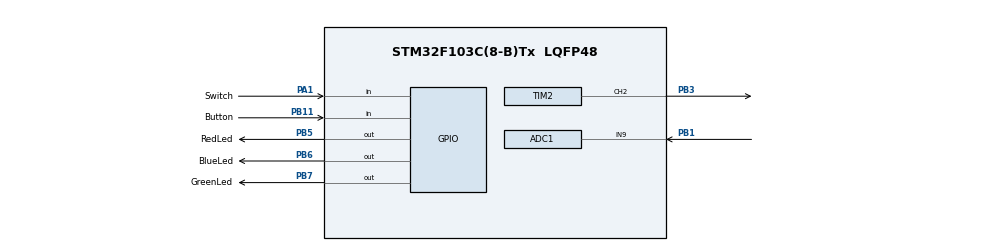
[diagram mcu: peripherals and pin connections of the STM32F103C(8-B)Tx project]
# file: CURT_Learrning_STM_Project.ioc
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Mcu.Family=STM32F1
RCC.PLLSourceVirtual=RCC_PLLSOURCE_HSE
ADC1.Rank-0\#ChannelRegularConversion=1
PD1-OSC_OUT.Mode=HSE-External-Oscillator
ADC1.ContinuousConvMode=ENABLE
PB11.GPIO_Label=Button
PB6.GPIO_Label=BlueLed
PD0-OSC_IN.Signal=RCC_OSC_IN
PB11.GPIO_PuPd=GPIO_PULLDOWN
TIM2.Channel-PWM\ Generation2\ CH2=TIM_CHANNEL_2
PB11.Signal=GPIO_Input
RCC.SYSCLKSource=RCC_SYSCLKSOURCE_HSE
ProjectManager.StackSize=0x400
PD1-OSC_OUT.Signal=RCC_OSC_OUT
PA13.Signal=SYS_JTMS-SWDIO
SH.S_TIM2_CH2.0=TIM2_CH2,PWM Generation2 CH2
ProjectManager.TargetToolchain=STM32CubeIDE
PB6.Signal=GPIO_Output
PB5.PinState=GPIO_PIN_RESET
RCC.USBFreq_Value=16000000
PA1.GPIO_PuPd=GPIO_PULLDOWN
PA1.Signal=GPIO_Input
PD0-OSC_IN.Mode=HSE-External-Oscillator
ADC1.Channel-0\#ChannelRegularConversion=ADC_CHANNEL_9
board=custom
RCC.APB2Freq_Value=8000000
VP_TIM2_VS_ClockSourceINT.Mode=Internal
PA14.Mode=Serial_Wire
PA1.GPIO_Label=Switch
PB7.Signal=GPIO_Output
TIM2.Period=624
PA13.Mode=Serial_Wire
Mcu.Name=STM32F103C(8-B)Tx
ADC1.SamplingTime-0\#ChannelRegularConversion=ADC_SAMPLETIME_1CYCLE_5
PB7.GPIO_Label=GreenLed
PB3.Signal=S_TIM2_CH2
Mcu.Package=LQFP48
PB5.Signal=GPIO_Output
TIM2.Prescaler=127
PB1.Signal=ADCx_IN9
ADC1.master=1
PB5.GPIO_PuPd=GPIO_PULLDOWN
PA14.Signal=SYS_JTCK-SWCLK
ProjectManager.HeapSize=0x200
SH.ADCx_IN9.0=ADC1_IN9,IN9
NVIC.PriorityGroup=NVIC_PRIORITYGROUP_4
ADC1.NbrOfConversionFlag=1
PB5.GPIO_Label=RedLed
RCC.APB1Freq_Value=8000000

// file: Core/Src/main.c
/* USER CODE BEGIN Header */
/**
  ******************************************************************************
  * @file           : main.c
  * @brief          : Main program body
  ******************************************************************************
  * @attention
  *
  * <h2><center>&copy; Copyright (c) 2024 STMicroelectronics.
  * All rights reserved.</center></h2>
  *
  * This software component is licensed by ST under BSD 3-Clause license,
  * the "License"; You may not use this file except in compliance with the
  * License. You may obtain a copy of the License at:
  *                        opensource.org/licenses/BSD-3-Clause
  *
  ******************************************************************************
  */
/* USER CODE END Header */
#include "main.h"

ADC_HandleTypeDef hadc1;

TIM_HandleTypeDef htim2;

void SystemClock_Config(void);
static void MX_GPIO_Init(void);
static void MX_ADC1_Init(void);
static void MX_TIM2_Init(void);

/* USER CODE BEGIN 0 */

uint32_t ADC_Value;

/* USER CODE END 0 */

int main(void)
{

  /* MCU Configuration--------------------------------------------------------*/

  /* Reset of all peripherals, Initializes the Flash interface and the Systick. */
  HAL_Init();

  /* Configure the system clock */
  SystemClock_Config();

  /* Initialize all configured peripherals */
  MX_GPIO_Init();
  MX_ADC1_Init();
  MX_TIM2_Init();
  /* USER CODE BEGIN 2 */

  HAL_TIM_PWM_Start(&htim2, TIM_CHANNEL_2);
  HAL_ADC_Start(&hadc1);
  /*SystemCoreClockUpdate();
  SysTick_Config(SystemCoreClock/100);
  SysTick -> CTRL = 0;
  SysTick -> VAL  = 0;
  SysTick -> CTRL = (SysTick_CTRL_CLKSOURCE_Msk | SysTick_CTRL_ENABLE_Msk | SysTick_CTRL_CLKSOURCE_Msk);*/

  /* USER CODE END 2 */

  /* Infinite loop */
  while (1)
  {

    /* USER CODE BEGIN 3 */

	  HAL_ADC_PollForConversion(&hadc1, 1000);
	  ADC_Value = HAL_ADC_GetValue(&hadc1);

	  if( HAL_GPIO_ReadPin(Switch_GPIO_Port, Switch_Pin) == 1)
	  {
		  __HAL_TIM_SET_COMPARE(&htim2, TIM_CHANNEL_2, ADC_Value);
		  //HAL_Delay(3);
	  }
	  else
	  {
		  __HAL_TIM_SET_COMPARE(&htim2, TIM_CHANNEL_2, 0);
	  }

	  if( HAL_GPIO_ReadPin(Button_GPIO_Port, Button_Pin) == 1)
	  {
	  	  HAL_GPIO_WritePin(RedLed_GPIO_Port, RedLed_Pin, 1);
	  	  //HAL_SYSTICK_Config(1000);

	  }

  }
  /* USER CODE END 3 */
}

void SysTick_Handler(void)
{
	if(HAL_GPIO_ReadPin(RedLed_GPIO_Port, RedLed_Pin) == 1)
	{
		HAL_IncTick();
	}

  if(uwTick >= 1000)
  {
	  HAL_GPIO_TogglePin(RedLed_GPIO_Port, RedLed_Pin);
	  uwTick = 0;
  }
  //HAL_GPIO_WritePin(RedLed_GPIO_Port, RedLed_Pin, GPIO_PIN_RESET);
}

void SystemClock_Config(void)
{
  RCC_OscInitTypeDef RCC_OscInitStruct = {0};
  RCC_ClkInitTypeDef RCC_ClkInitStruct = {0};
  RCC_PeriphCLKInitTypeDef PeriphClkInit = {0};

  /** Initializes the RCC Oscillators according to the specified parameters
  * in the RCC_OscInitTypeDef structure.
  */
  RCC_OscInitStruct.OscillatorType = RCC_OSCILLATORTYPE_HSE;
  RCC_OscInitStruct.HSEState = RCC_HSE_ON;
  RCC_OscInitStruct.PLL.PLLState = RCC_PLL_NONE;
  if (HAL_RCC_OscConfig(&RCC_OscInitStruct) != HAL_OK)
  {
    Error_Handler();
  }
  /** Initializes the CPU, AHB and APB buses clocks
  */
  RCC_ClkInitStruct.ClockType = RCC_CLOCKTYPE_HCLK|RCC_CLOCKTYPE_SYSCLK
                              |RCC_CLOCKTYPE_PCLK1|RCC_CLOCKTYPE_PCLK2;
  RCC_ClkInitStruct.SYSCLKSource = RCC_SYSCLKSOURCE_HSE;
  RCC_ClkInitStruct.AHBCLKDivider = RCC_SYSCLK_DIV1;
  RCC_ClkInitStruct.APB1CLKDivider = RCC_HCLK_DIV1;
  RCC_ClkInitStruct.APB2CLKDivider = RCC_HCLK_DIV1;

  if (HAL_RCC_ClockConfig(&RCC_ClkInitStruct, FLASH_LATENCY_0) != HAL_OK)
  {
    Error_Handler();
  }
  PeriphClkInit.PeriphClockSelection = RCC_PERIPHCLK_ADC;
  PeriphClkInit.AdcClockSelection = RCC_ADCPCLK2_DIV2;
  if (HAL_RCCEx_PeriphCLKConfig(&PeriphClkInit) != HAL_OK)
  {
    Error_Handler();
  }
}

static void MX_ADC1_Init(void)
{

  ADC_ChannelConfTypeDef sConfig = {0};

  /** Common config
  */
  hadc1.Instance = ADC1;
  hadc1.Init.ScanConvMode = ADC_SCAN_DISABLE;
  hadc1.Init.ContinuousConvMode = ENABLE;
  hadc1.Init.DiscontinuousConvMode = DISABLE;
  hadc1.Init.ExternalTrigConv = ADC_SOFTWARE_START;
  hadc1.Init.DataAlign = ADC_DATAALIGN_RIGHT;
  hadc1.Init.NbrOfConversion = 1;
  if (HAL_ADC_Init(&hadc1) != HAL_OK)
  {
    Error_Handler();
  }
  /** Configure Regular Channel
  */
  sConfig.Channel = ADC_CHANNEL_9;
  sConfig.Rank = ADC_REGULAR_RANK_1;
  sConfig.SamplingTime = ADC_SAMPLETIME_1CYCLE_5;
  if (HAL_ADC_ConfigChannel(&hadc1, &sConfig) != HAL_OK)
  {
    Error_Handler();
  }

}

static void MX_TIM2_Init(void)
{

  TIM_ClockConfigTypeDef sClockSourceConfig = {0};
  TIM_MasterConfigTypeDef sMasterConfig = {0};
  TIM_OC_InitTypeDef sConfigOC = {0};

  htim2.Instance = TIM2;
  htim2.Init.Prescaler = 127;
  htim2.Init.CounterMode = TIM_COUNTERMODE_UP;
  htim2.Init.Period = 624;
  htim2.Init.ClockDivision = TIM_CLOCKDIVISION_DIV1;
  htim2.Init.AutoReloadPreload = TIM_AUTORELOAD_PRELOAD_DISABLE;
  if (HAL_TIM_Base_Init(&htim2) != HAL_OK)
  {
    Error_Handler();
  }
  sClockSourceConfig.ClockSource = TIM_CLOCKSOURCE_INTERNAL;
  if (HAL_TIM_ConfigClockSource(&htim2, &sClockSourceConfig) != HAL_OK)
  {
    Error_Handler();
  }
  if (HAL_TIM_PWM_Init(&htim2) != HAL_OK)
  {
    Error_Handler();
  }
  sMasterConfig.MasterOutputTrigger = TIM_TRGO_RESET;
  sMasterConfig.MasterSlaveMode = TIM_MASTERSLAVEMODE_DISABLE;
  if (HAL_TIMEx_MasterConfigSynchronization(&htim2, &sMasterConfig) != HAL_OK)
  {
    Error_Handler();
  }
  sConfigOC.OCMode = TIM_OCMODE_PWM1;
  sConfigOC.Pulse = 0;
  sConfigOC.OCPolarity = TIM_OCPOLARITY_HIGH;
  sConfigOC.OCFastMode = TIM_OCFAST_DISABLE;
  if (HAL_TIM_PWM_ConfigChannel(&htim2, &sConfigOC, TIM_CHANNEL_2) != HAL_OK)
  {
    Error_Handler();
  }
  HAL_TIM_MspPostInit(&htim2);

}

static void MX_GPIO_Init(void)
{
  GPIO_InitTypeDef GPIO_InitStruct = {0};

  /* GPIO Ports Clock Enable */
  __HAL_RCC_GPIOD_CLK_ENABLE();
  __HAL_RCC_GPIOA_CLK_ENABLE();
  __HAL_RCC_GPIOB_CLK_ENABLE();

  /*Configure GPIO pin Output Level */
  HAL_GPIO_WritePin(GPIOB, RedLed_Pin|BlueLed_Pin|GreenLed_Pin, GPIO_PIN_RESET);

  /*Configure GPIO pin : Switch_Pin */
  GPIO_InitStruct.Pin = Switch_Pin;
  GPIO_InitStruct.Mode = GPIO_MODE_INPUT;
  GPIO_InitStruct.Pull = GPIO_PULLDOWN;
  HAL_GPIO_Init(Switch_GPIO_Port, &GPIO_InitStruct);

  /*Configure GPIO pin : Button_Pin */
  GPIO_InitStruct.Pin = Button_Pin;
  GPIO_InitStruct.Mode = GPIO_MODE_INPUT;
  GPIO_InitStruct.Pull = GPIO_PULLDOWN;
  HAL_GPIO_Init(Button_GPIO_Port, &GPIO_InitStruct);

  /*Configure GPIO pin : RedLed_Pin */
  GPIO_InitStruct.Pin = RedLed_Pin;
  GPIO_InitStruct.Mode = GPIO_MODE_OUTPUT_PP;
  GPIO_InitStruct.Pull = GPIO_PULLDOWN;
  GPIO_InitStruct.Speed = GPIO_SPEED_FREQ_LOW;
  HAL_GPIO_Init(RedLed_GPIO_Port, &GPIO_InitStruct);

  /*Configure GPIO pins : BlueLed_Pin GreenLed_Pin */
  GPIO_InitStruct.Pin = BlueLed_Pin|GreenLed_Pin;
  GPIO_InitStruct.Mode = GPIO_MODE_OUTPUT_PP;
  GPIO_InitStruct.Pull = GPIO_NOPULL;
  GPIO_InitStruct.Speed = GPIO_SPEED_FREQ_LOW;
  HAL_GPIO_Init(GPIOB, &GPIO_InitStruct);

}

void Error_Handler(void)
{
  __disable_irq();
  while (1)
  {
  }
}

/************************ (C) COPYRIGHT STMicroelectronics *****END OF FILE****/
